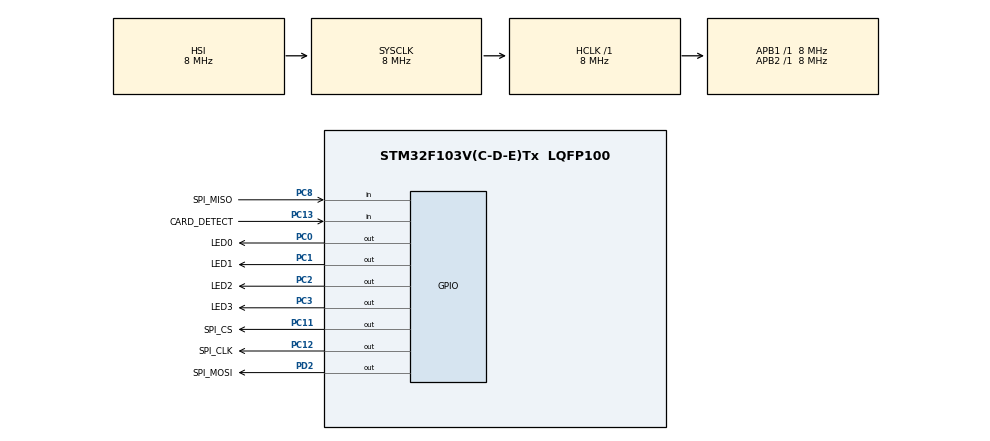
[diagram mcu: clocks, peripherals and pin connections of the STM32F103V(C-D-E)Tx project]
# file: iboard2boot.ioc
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Mcu.Family=STM32F1
Mcu.Name=STM32F103V(C-D-E)Tx
Mcu.Package=LQFP100
NVIC.PriorityGroup=NVIC_PRIORITYGROUP_4
PA13.Mode=Serial_Wire
PA13.Signal=SYS_JTMS-SWDIO
PA14.Mode=Serial_Wire
PA14.Signal=SYS_JTCK-SWCLK
PC0.GPIO_Label=LED0
PC0.Signal=GPIO_Output
PC1.GPIO_Label=LED1
PC1.Signal=GPIO_Output
PC11.GPIO_Label=SPI_CS
PC11.Signal=GPIO_Output
PC12.GPIO_Label=SPI_CLK
PC12.Signal=GPIO_Output
PC13-TAMPER-RTC.GPIO_Label=CARD_DETECT
PC13-TAMPER-RTC.Signal=GPIO_Input
PC2.GPIO_Label=LED2
PC2.Signal=GPIO_Output
PC3.GPIO_Label=LED3
PC3.Signal=GPIO_Output
PC8.GPIO_Label=SPI_MISO
PC8.Signal=GPIO_Input
PD2.GPIO_Label=SPI_MOSI
PD2.Signal=GPIO_Output
ProjectManager.HeapSize=0x200
ProjectManager.StackSize=0x400
ProjectManager.TargetToolchain=STM32CubeIDE
RCC.AHBFreq_Value=8000000
RCC.APB1Freq_Value=8000000
RCC.APB1TimFreq_Value=8000000
RCC.APB2Freq_Value=8000000
RCC.APB2TimFreq_Value=8000000
RCC.HCLKFreq_Value=8000000
RCC.SYSCLKFreq_VALUE=8000000
RCC.USBFreq_Value=8000000
board=custom

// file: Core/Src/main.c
/* USER CODE BEGIN Header */
/**
  ******************************************************************************
  * @file           : main.c
  * @brief          : Main program body
  ******************************************************************************
  * @attention
  *
  * Copyright (c) 2022 STMicroelectronics.
  * All rights reserved.
  *
  * This software is licensed under terms that can be found in the LICENSE file
  * in the root directory of this software component.
  * If no LICENSE file comes with this software, it is provided AS-IS.
  *
  ******************************************************************************
  */
/* USER CODE END Header */
#include "main.h"

/* USER CODE BEGIN Includes */
#include "bootloader.h"
/* USER CODE END Includes */

void SystemClock_Config(void);
static void MX_GPIO_Init(void);

int main(void)
{
  /* USER CODE BEGIN 1 */
	// THIS PROJECT WILL BRICK THE STM32. MOST LIKELY DUE TO THE SD CARD
	// INTERFACE. CAN BE RECOVERED SOMEHOW BY FIDDLINE WITH OPTION BYTES RESET
	// USING STLINK-UTILITY AND HOT-PLUG AND RESET HOLD DOWN DURING ENTIRE TIME
  /* USER CODE END 1 */

  /* MCU Configuration--------------------------------------------------------*/

  /* Reset of all peripherals, Initializes the Flash interface and the Systick. */
  HAL_Init();

  /* Configure the system clock */
  SystemClock_Config();

  /* Initialize all configured peripherals */
  MX_GPIO_Init();
  /* USER CODE BEGIN 2 */
  bootloader();
  /* USER CODE END 2 */

  /* Infinite loop */
  while (1)
  {

  }
}

void SystemClock_Config(void)
{
  RCC_OscInitTypeDef RCC_OscInitStruct = {0};
  RCC_ClkInitTypeDef RCC_ClkInitStruct = {0};

  /** Initializes the RCC Oscillators according to the specified parameters
  * in the RCC_OscInitTypeDef structure.
  */
  RCC_OscInitStruct.OscillatorType = RCC_OSCILLATORTYPE_HSI;
  RCC_OscInitStruct.HSIState = RCC_HSI_ON;
  RCC_OscInitStruct.HSICalibrationValue = RCC_HSICALIBRATION_DEFAULT;
  RCC_OscInitStruct.PLL.PLLState = RCC_PLL_NONE;
  if (HAL_RCC_OscConfig(&RCC_OscInitStruct) != HAL_OK)
  {
    Error_Handler();
  }

  /** Initializes the CPU, AHB and APB buses clocks
  */
  RCC_ClkInitStruct.ClockType = RCC_CLOCKTYPE_HCLK|RCC_CLOCKTYPE_SYSCLK
                              |RCC_CLOCKTYPE_PCLK1|RCC_CLOCKTYPE_PCLK2;
  RCC_ClkInitStruct.SYSCLKSource = RCC_SYSCLKSOURCE_HSI;
  RCC_ClkInitStruct.AHBCLKDivider = RCC_SYSCLK_DIV1;
  RCC_ClkInitStruct.APB1CLKDivider = RCC_HCLK_DIV1;
  RCC_ClkInitStruct.APB2CLKDivider = RCC_HCLK_DIV1;

  if (HAL_RCC_ClockConfig(&RCC_ClkInitStruct, FLASH_LATENCY_0) != HAL_OK)
  {
    Error_Handler();
  }
}

static void MX_GPIO_Init(void)
{
  GPIO_InitTypeDef GPIO_InitStruct = {0};

  /* GPIO Ports Clock Enable */
  __HAL_RCC_GPIOC_CLK_ENABLE();
  __HAL_RCC_GPIOA_CLK_ENABLE();
  __HAL_RCC_GPIOD_CLK_ENABLE();

  /*Configure GPIO pin Output Level */
  HAL_GPIO_WritePin(GPIOC, LED0_Pin|LED1_Pin|LED2_Pin|LED3_Pin
                          |SPI_CS_Pin|SPI_CLK_Pin, GPIO_PIN_RESET);

  /*Configure GPIO pin Output Level */
  HAL_GPIO_WritePin(SPI_MOSI_GPIO_Port, SPI_MOSI_Pin, GPIO_PIN_RESET);

  /*Configure GPIO pins : CARD_DETECT_Pin SPI_MISO_Pin */
  GPIO_InitStruct.Pin = CARD_DETECT_Pin|SPI_MISO_Pin;
  GPIO_InitStruct.Mode = GPIO_MODE_INPUT;
  GPIO_InitStruct.Pull = GPIO_NOPULL;
  HAL_GPIO_Init(GPIOC, &GPIO_InitStruct);

  /*Configure GPIO pins : LED0_Pin LED1_Pin LED2_Pin LED3_Pin
                           SPI_CS_Pin SPI_CLK_Pin */
  GPIO_InitStruct.Pin = LED0_Pin|LED1_Pin|LED2_Pin|LED3_Pin
                          |SPI_CS_Pin|SPI_CLK_Pin;
  GPIO_InitStruct.Mode = GPIO_MODE_OUTPUT_PP;
  GPIO_InitStruct.Pull = GPIO_NOPULL;
  GPIO_InitStruct.Speed = GPIO_SPEED_FREQ_LOW;
  HAL_GPIO_Init(GPIOC, &GPIO_InitStruct);

  /*Configure GPIO pin : SPI_MOSI_Pin */
  GPIO_InitStruct.Pin = SPI_MOSI_Pin;
  GPIO_InitStruct.Mode = GPIO_MODE_OUTPUT_PP;
  GPIO_InitStruct.Pull = GPIO_NOPULL;
  GPIO_InitStruct.Speed = GPIO_SPEED_FREQ_LOW;
  HAL_GPIO_Init(SPI_MOSI_GPIO_Port, &GPIO_InitStruct);

}

void Error_Handler(void)
{
  __disable_irq();
  while (1)
  {
  }
}
